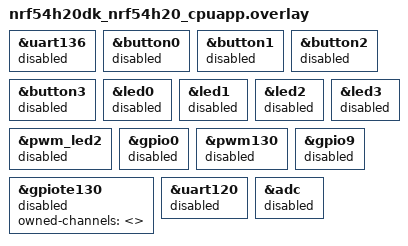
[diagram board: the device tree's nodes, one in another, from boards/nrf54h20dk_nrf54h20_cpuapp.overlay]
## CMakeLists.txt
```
# SPDX-License-Identifier: Apache-2.0

cmake_minimum_required(VERSION 3.20.0)

find_package(Zephyr REQUIRED HINTS $ENV{ZEPHYR_BASE})
project(coproc_launcher)

if(CONFIG_NRF_REMOTE_IMAGE_INC_DIR)
  zephyr_include_directories(${CONFIG_NRF_REMOTE_IMAGE_INC_DIR})
endif()

target_sources(app PRIVATE src/main.c)
```

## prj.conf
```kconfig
# Copyright (c) 2026 Nordic Semiconductor ASA
# SPDX-License-Identifier: Apache-2.0

CONFIG_BOOT_BANNER=n
```

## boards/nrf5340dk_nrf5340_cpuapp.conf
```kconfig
# Copyright (c) 2026 Nordic Semiconductor ASA
# SPDX-License-Identifier: Apache-2.0

CONFIG_CLOCK_CONTROL_NRF=n
```

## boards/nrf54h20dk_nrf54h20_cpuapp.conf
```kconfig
# Copyright (c) 2026 Nordic Semiconductor ASA
# SPDX-License-Identifier: Apache-2.0

# Free GPIO and UART for coprocessors
CONFIG_GPIO=n
CONFIG_SERIAL=n
CONFIG_CONSOLE=n
CONFIG_UART_CONSOLE=n

CONFIG_PM=y
```

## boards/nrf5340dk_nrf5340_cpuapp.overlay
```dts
/*
 * Copyright (c) 2026 Nordic Semiconductor ASA
 *
 * SPDX-License-Identifier: Apache-2.0
 */

/ {
	nrf-gpio-forwarder {
		compatible = "nordic,nrf-gpio-forwarder";
		status = "okay";

		all {
			/* P0.0 and P0.1 allocated to LFXO */
			gpios = <&gpio0 2 0>,
				<&gpio0 3 0>,
				<&gpio0 4 0>,
				<&gpio0 5 0>,
				<&gpio0 6 0>,
				<&gpio0 7 0>,
				<&gpio0 8 0>,
				<&gpio0 9 0>,
				<&gpio0 10 0>,
				<&gpio0 11 0>,
				<&gpio0 12 0>,
				<&gpio0 13 0>,
				<&gpio0 14 0>,
				<&gpio0 15 0>,
				<&gpio0 16 0>,
				<&gpio0 17 0>,
				<&gpio0 18 0>,
				<&gpio0 19 0>,
				<&gpio0 20 0>,
				<&gpio0 21 0>,
				<&gpio0 22 0>,
				<&gpio0 23 0>,
				<&gpio0 24 0>,
				<&gpio0 25 0>,
				<&gpio0 26 0>,
				<&gpio0 27 0>,
				<&gpio0 28 0>,
				<&gpio0 29 0>,
				<&gpio0 30 0>,
				<&gpio0 31 0>,
				<&gpio1 0 0>,
				<&gpio1 1 0>,
				<&gpio1 2 0>,
				<&gpio1 3 0>,
				<&gpio1 4 0>,
				<&gpio1 5 0>,
				<&gpio1 6 0>,
				<&gpio1 7 0>,
				<&gpio1 8 0>,
				<&gpio1 9 0>,
				<&gpio1 10 0>,
				<&gpio1 11 0>,
				<&gpio1 12 0>,
				<&gpio1 13 0>,
				<&gpio1 14 0>,
				<&gpio1 15 0>;
		};
	};
};
```

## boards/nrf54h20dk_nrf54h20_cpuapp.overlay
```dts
/*
 * Copyright (c) 2026 Nordic Semiconductor ASA
 *
 * SPDX-License-Identifier: Apache-2.0
 */

&uart136 {
	status = "disabled";
};

&button0 {
	status = "disabled";
};

&button1 {
	status = "disabled";
};

&button2 {
	status = "disabled";
};

&button3 {
	status = "disabled";
};

&led0 {
	status = "disabled";
};

&led1 {
	status = "disabled";
};

&led2 {
	status = "disabled";
};

&led3 {
	status = "disabled";
};

&pwm_led2 {
	status = "disabled";
};

&gpio0 {
	status = "disabled";
};

&pwm130 {
	status = "disabled";
};

&gpiote130 {
	status = "disabled";
	owned-channels = <>;
};

&gpio9 {
	status = "disabled";
};

&uart120 {
	status = "disabled";
};

&adc {
	status = "disabled";
};
```

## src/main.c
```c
/*
 * Copyright (c) 2026 Nordic Semiconductor ASA
 *
 * SPDX-License-Identifier: Apache-2.0
 */

int main(void)
{
	return 0;
}
```
